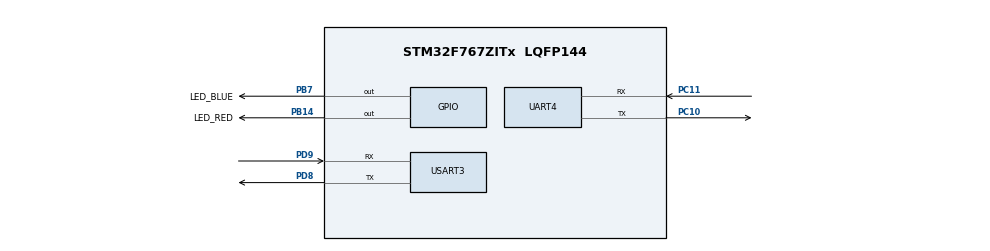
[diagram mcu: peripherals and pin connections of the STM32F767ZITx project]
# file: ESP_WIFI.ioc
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CORTEX_M7.default_mode_Activation=1
Dma.Request0=UART4_RX
Dma.UART4_RX.0.Direction=DMA_PERIPH_TO_MEMORY
Dma.UART4_RX.0.FIFOMode=DMA_FIFOMODE_DISABLE
Dma.UART4_RX.0.Instance=DMA1_Stream2
Dma.UART4_RX.0.MemDataAlignment=DMA_MDATAALIGN_BYTE
Dma.UART4_RX.0.MemInc=DMA_MINC_ENABLE
Dma.UART4_RX.0.Mode=DMA_NORMAL
Dma.UART4_RX.0.PeriphDataAlignment=DMA_PDATAALIGN_BYTE
Dma.UART4_RX.0.PeriphInc=DMA_PINC_DISABLE
Dma.UART4_RX.0.Priority=DMA_PRIORITY_LOW
Mcu.Family=STM32F7
Mcu.Name=STM32F767ZITx
Mcu.Package=LQFP144
NVIC.DMA1_Stream2_IRQn=true\:0\:0\:false\:false\:true\:false\:true\:true
NVIC.PriorityGroup=NVIC_PRIORITYGROUP_4
NVIC.UART4_IRQn=true\:0\:0\:true\:false\:true\:true\:true\:true
PB14.GPIO_Label=LED_RED
PB14.Signal=GPIO_Output
PB7.GPIO_Label=LED_BLUE
PB7.Signal=GPIO_Output
PC10.Mode=Asynchronous
PC10.Signal=UART4_TX
PC11.Mode=Asynchronous
PC11.Signal=UART4_RX
PD8.Mode=Asynchronous
PD8.Signal=USART3_TX
PD9.Mode=Asynchronous
PD9.Signal=USART3_RX
ProjectManager.HeapSize=0x200
ProjectManager.StackSize=0x400
ProjectManager.TargetToolchain=STM32CubeIDE
RCC.HSE_VALUE=25000000
RCC.HSI_VALUE=16000000
RCC.LSE_VALUE=32768
RCC.USBFreq_Value=96000000
RCC.VCOOutputFreq_Value=192000000
USART3.VirtualMode-Asynchronous=VM_ASYNC
board=custom

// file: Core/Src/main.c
/* USER CODE BEGIN Header */
/**
  ******************************************************************************
  * @file           : main.c
  * @brief          : Main program body
  ******************************************************************************
  * @attention
  *
  * Copyright (c) 2024 STMicroelectronics.
  * All rights reserved.
  *
  * This software is licensed under terms that can be found in the LICENSE file
  * in the root directory of this software component.
  * If no LICENSE file comes with this software, it is provided AS-IS.
  *
  ******************************************************************************
  */
/* USER CODE END Header */
#include "main.h"

/* USER CODE BEGIN Includes */
#include <stdint.h>
#include <stdio.h>
#include <string.h> //Temporary...
#include "WIFI.h"
/* USER CODE END Includes */

UART_HandleTypeDef huart4;
UART_HandleTypeDef huart3;
DMA_HandleTypeDef hdma_uart4_rx;

void SystemClock_Config(void);
static void MPU_Config(void);
static void MX_GPIO_Init(void);
static void MX_DMA_Init(void);
static void MX_UART4_Init(void);
static void MX_USART3_UART_Init(void);

/* USER CODE BEGIN 0 */
int _write(int file, char *ptr, int len){
	HAL_UART_Transmit(&huart3, (uint8_t*)ptr, len, HAL_MAX_DELAY);//function for printf() to print to UART Serial console
	return len;
}

/* USER CODE END 0 */

int main(void)
{

  /* MPU Configuration--------------------------------------------------------*/
  MPU_Config();

  /* MCU Configuration--------------------------------------------------------*/

  /* Reset of all peripherals, Initializes the Flash interface and the Systick. */
  HAL_Init();

  /* Configure the system clock */
  SystemClock_Config();

  /* Initialize all configured peripherals */
  MX_GPIO_Init();
  MX_DMA_Init();
  MX_UART4_Init();
  MX_USART3_UART_Init();
  /* USER CODE BEGIN 2 */
  HAL_UARTEx_ReceiveToIdle_DMA(&huart4, UART4_RX, RXSIZE);
  ATStatus test;
  WifiMode queryMode=Null;
  char output[1028];
  /* USER CODE END 2 */

  /* Infinite loop */
  while (1)
  {

    /* USER CODE BEGIN 3 */
	  test = AT_setWIFImode(&huart4,AP);
	  test = AT_queryWIFImode(&huart4,&queryMode);

	  HAL_Delay(1000);
  }
  /* USER CODE END 3 */
}

void SystemClock_Config(void)
{
  RCC_OscInitTypeDef RCC_OscInitStruct = {0};
  RCC_ClkInitTypeDef RCC_ClkInitStruct = {0};

  /** Configure the main internal regulator output voltage
  */
  __HAL_RCC_PWR_CLK_ENABLE();
  __HAL_PWR_VOLTAGESCALING_CONFIG(PWR_REGULATOR_VOLTAGE_SCALE3);

  /** Initializes the RCC Oscillators according to the specified parameters
  * in the RCC_OscInitTypeDef structure.
  */
  RCC_OscInitStruct.OscillatorType = RCC_OSCILLATORTYPE_HSI;
  RCC_OscInitStruct.HSIState = RCC_HSI_ON;
  RCC_OscInitStruct.HSICalibrationValue = RCC_HSICALIBRATION_DEFAULT;
  RCC_OscInitStruct.PLL.PLLState = RCC_PLL_NONE;
  if (HAL_RCC_OscConfig(&RCC_OscInitStruct) != HAL_OK)
  {
    Error_Handler();
  }

  /** Initializes the CPU, AHB and APB buses clocks
  */
  RCC_ClkInitStruct.ClockType = RCC_CLOCKTYPE_HCLK|RCC_CLOCKTYPE_SYSCLK
                              |RCC_CLOCKTYPE_PCLK1|RCC_CLOCKTYPE_PCLK2;
  RCC_ClkInitStruct.SYSCLKSource = RCC_SYSCLKSOURCE_HSI;
  RCC_ClkInitStruct.AHBCLKDivider = RCC_SYSCLK_DIV1;
  RCC_ClkInitStruct.APB1CLKDivider = RCC_HCLK_DIV1;
  RCC_ClkInitStruct.APB2CLKDivider = RCC_HCLK_DIV1;

  if (HAL_RCC_ClockConfig(&RCC_ClkInitStruct, FLASH_LATENCY_0) != HAL_OK)
  {
    Error_Handler();
  }
}

static void MX_UART4_Init(void)
{

  huart4.Instance = UART4;
  huart4.Init.BaudRate = 115200;
  huart4.Init.WordLength = UART_WORDLENGTH_8B;
  huart4.Init.StopBits = UART_STOPBITS_1;
  huart4.Init.Parity = UART_PARITY_NONE;
  huart4.Init.Mode = UART_MODE_TX_RX;
  huart4.Init.HwFlowCtl = UART_HWCONTROL_NONE;
  huart4.Init.OverSampling = UART_OVERSAMPLING_16;
  huart4.Init.OneBitSampling = UART_ONE_BIT_SAMPLE_DISABLE;
  huart4.AdvancedInit.AdvFeatureInit = UART_ADVFEATURE_NO_INIT;
  if (HAL_UART_Init(&huart4) != HAL_OK)
  {
    Error_Handler();
  }

}

static void MX_USART3_UART_Init(void)
{

  huart3.Instance = USART3;
  huart3.Init.BaudRate = 115200;
  huart3.Init.WordLength = UART_WORDLENGTH_8B;
  huart3.Init.StopBits = UART_STOPBITS_1;
  huart3.Init.Parity = UART_PARITY_NONE;
  huart3.Init.Mode = UART_MODE_TX_RX;
  huart3.Init.HwFlowCtl = UART_HWCONTROL_NONE;
  huart3.Init.OverSampling = UART_OVERSAMPLING_16;
  huart3.Init.OneBitSampling = UART_ONE_BIT_SAMPLE_DISABLE;
  huart3.AdvancedInit.AdvFeatureInit = UART_ADVFEATURE_NO_INIT;
  if (HAL_UART_Init(&huart3) != HAL_OK)
  {
    Error_Handler();
  }

}

static void MX_DMA_Init(void)
{

  /* DMA controller clock enable */
  __HAL_RCC_DMA1_CLK_ENABLE();

  /* DMA interrupt init */
  /* DMA1_Stream2_IRQn interrupt configuration */
  HAL_NVIC_SetPriority(DMA1_Stream2_IRQn, 0, 0);
  HAL_NVIC_EnableIRQ(DMA1_Stream2_IRQn);

}

static void MX_GPIO_Init(void)
{
  GPIO_InitTypeDef GPIO_InitStruct = {0};

  /* GPIO Ports Clock Enable */
  __HAL_RCC_GPIOB_CLK_ENABLE();
  __HAL_RCC_GPIOD_CLK_ENABLE();
  __HAL_RCC_GPIOC_CLK_ENABLE();

  /*Configure GPIO pin Output Level */
  HAL_GPIO_WritePin(GPIOB, LED_RED_Pin|LED_BLUE_Pin, GPIO_PIN_RESET);

  /*Configure GPIO pins : LED_RED_Pin LED_BLUE_Pin */
  GPIO_InitStruct.Pin = LED_RED_Pin|LED_BLUE_Pin;
  GPIO_InitStruct.Mode = GPIO_MODE_OUTPUT_PP;
  GPIO_InitStruct.Pull = GPIO_NOPULL;
  GPIO_InitStruct.Speed = GPIO_SPEED_FREQ_LOW;
  HAL_GPIO_Init(GPIOB, &GPIO_InitStruct);

}

 /* MPU Configuration */

void MPU_Config(void)
{
  MPU_Region_InitTypeDef MPU_InitStruct = {0};

  /* Disables the MPU */
  HAL_MPU_Disable();

  /** Initializes and configures the Region and the memory to be protected
  */
  MPU_InitStruct.Enable = MPU_REGION_ENABLE;
  MPU_InitStruct.Number = MPU_REGION_NUMBER0;
  MPU_InitStruct.BaseAddress = 0x0;
  MPU_InitStruct.Size = MPU_REGION_SIZE_4GB;
  MPU_InitStruct.SubRegionDisable = 0x87;
  MPU_InitStruct.TypeExtField = MPU_TEX_LEVEL0;
  MPU_InitStruct.AccessPermission = MPU_REGION_NO_ACCESS;
  MPU_InitStruct.DisableExec = MPU_INSTRUCTION_ACCESS_DISABLE;
  MPU_InitStruct.IsShareable = MPU_ACCESS_SHAREABLE;
  MPU_InitStruct.IsCacheable = MPU_ACCESS_NOT_CACHEABLE;
  MPU_InitStruct.IsBufferable = MPU_ACCESS_NOT_BUFFERABLE;

  HAL_MPU_ConfigRegion(&MPU_InitStruct);
  /* Enables the MPU */
  HAL_MPU_Enable(MPU_PRIVILEGED_DEFAULT);

}

void Error_Handler(void)
{
  __disable_irq();
  while (1)
  {
  }
}
